# Register Definitions: IP-XACT component
VLNV meklort:<PROJECT>:Register Definitions:1.0

## Address spaces and blocks
APE.APE: base 0xC0010000, range , width , register
APE_PERI.APE_PERI: base 0xC0018000, range , width 

## Registers
Registers are 32-bit, read-write, no defined reset value unless marked. A register's access mark holds for its fields unless they carry their own. Offsets are from the block's base; lines under a group give offsets from that group; [hi:lo] are bit positions; {n}, {i} and the like mark numbered series; 'fields as' and 'values as' point back to an identical list; <NAME> marks a mode.

## APE.APE — Device APE Registers
Base 0xC0010000
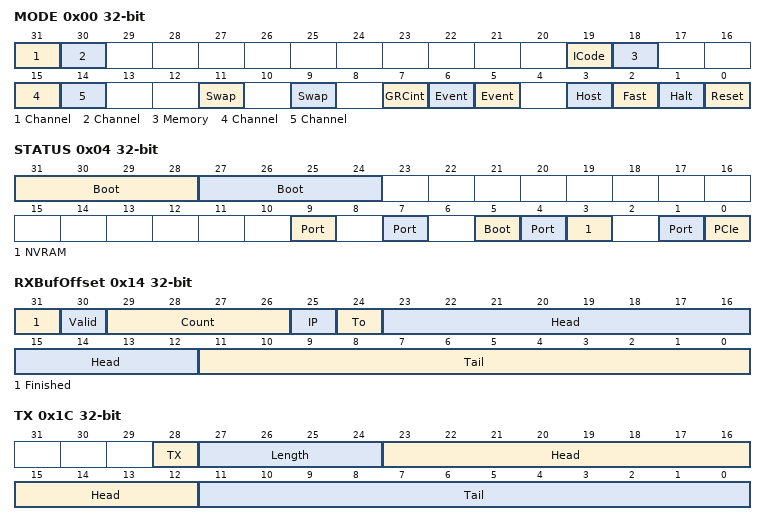
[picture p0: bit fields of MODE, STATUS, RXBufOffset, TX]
0x00 MODE — More of these bits can be found in diagnostic utilities, but they don't seem too interesting.
  [31] Channel 3 Enable
  [30] Channel 1 Enable
  [19] ICode PIP Rd Disable
  [18] Memory ECC
  [15] Channel 2 Enable
  [14] Channel 0 Enable
  [11] Swap ARB dword
  [9] Swap ATB dword
  [7] GRCint
  [6] Event 2
  [5] Event 1 — Used to signal the APE that an event from the host is ready for processing in SHM.
  [3] Host Diag
  [2] Fast Boot — Can be used to boot from RAM instead of NVM. Takes a full APE image with section headers, etc. so you still need to form a proper image.
  [1] Halt — APE is halted if set. Setting then unsetting this bit resets the APE to its reset vector, etc.
  [0] Reset — Used to reset the APE block.
0x04 STATUS
  [31:28] Boot Status A
    0=None; 1=NMI Exception; 2=Fault Exception; 3=Memory Check; 4=Unknown 4; 5=Romloader Disabled; 6=Magic Number; 7=APE Init Code; 8=Header Checksum; 9=APE Header; 10=Image Checksum; 11=NVRAM Checksum; 12=Invalid Type; 13=ROM Loader Checksum; 14=Invalid Unzip Len; 15=Unknown F
  [27:24] Boot Status B
    0=Prog 0; 1=Prog 1; 2=BPC Enter; 3=Decode; 4=Read NVRAM Header; 5=Read Code; 6=Jump; 7=Prog 7; 8=BPC Success
  [9] Port 1 D State — Indicates port is in D3 if set, otherwise the port is in D0-D2.
  [7] Port 1 GRC Reset
  [5] Boot Mode
    0=NVRAM; 1=Fast
  [4] Port 0 D State — Indicates port is in D3 if set, otherwise the port is in D0-D2.
  [3] NVRAM Control Reset
  [1] Port 0 GRC Reset
  [0] PCIe Reset
0x08 GPIO_MESSAGE access not given — Related to APE fastboot. In that case the value of it is an APE memory address in the code region. If Fast Boot is set, and the low two bits of this are not 0b10, ROM hangs (you have to OR 0x2 into the address). Otherwise, they are masked off and the resulting value is used as the reset vector. The resulting value is also stored in this register (i.e., the low two bits are cleared).
0x0C EVENT
  [0] 1 — Event 1
0x14 RXBufOffset Func0 — This is examined on the APE Packet RX interrupt, and indicates the offset of an incoming (from-network) frame within the APE memory space, which provides access to the from-network RX buffer. The fields are block numbers (block size 128 bytes).
  [31] Finished, [30] Valid, [29:26] Count, [25] IP Frag, [24] To Host, [23:12] Head, [11:0] Tail
0x18 RXBufOffset Func1 size not given access not given — This is examined on the APE Packet RX interrupt, and indicates the offset of an incoming (from-network) frame within the APE memory space, which provides access to the from-network RX buffer.
0x1C TX To Net Doorbell Func0 — Written on APE TX to network after filling 0xA002 buffer with packet.
  [28] TX Queue Full, [27:24] Length, [23:12] Head, [11:0] Tail
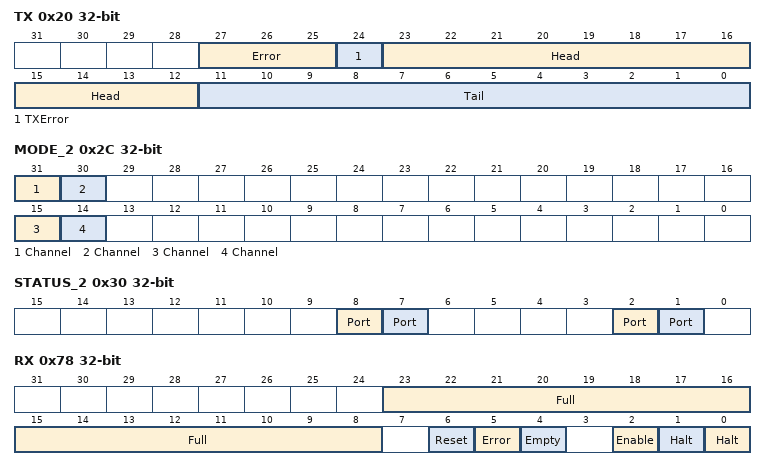
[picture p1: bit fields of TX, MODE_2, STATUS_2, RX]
0x20 TX State0 — APE TX Status Port0
  [27:25] Error Code
    1=Frame Length Mismatch; 2=MBuf Count Mismatch
  [24] TXError
  [23:12] Head
  [11:0] Tail
0x24 TX State1 size not given access not given — APE TX State Port1
0x2C MODE_2 — Expansion for MODE
  [31] Channel 3 Enable, [30] Channel 1 Enable, [15] Channel 2 Enable, [14] Channel 0 Enable
0x30 STATUS_2
  [8] Port 3 D State
  [7] Port 3 GRC Reset — Indicates port is in D3 if set, otherwise the port is in D0-D2.
  [2] Port 2 D State — Indicates port is in D3 if set, otherwise the port is in D0-D2.
  [1] Port 2 GRC Reset
0x4C LOCK_GRANT__OBSOLETE_ access not given — See
0x78 RX Pool Mode Status 0
  [23:8] Full Count, [6] Reset, [5] Error, [4] Empty, [2] Enable, [1] Halt Done, [0] Halt
0x7C RX Pool Mode Status 1 size not given access not given
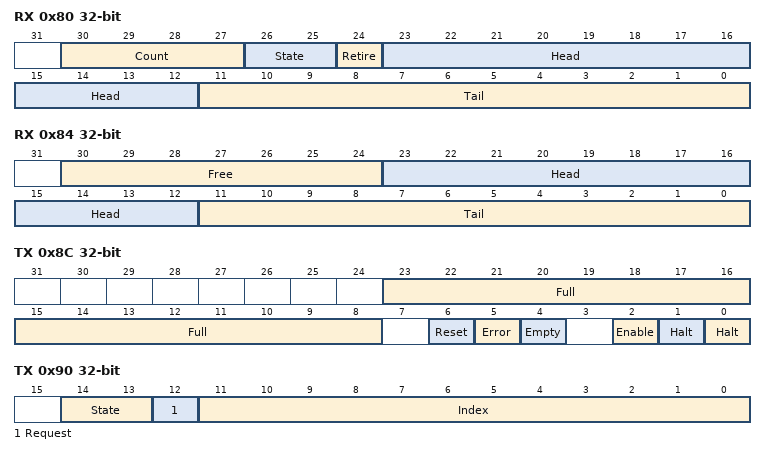
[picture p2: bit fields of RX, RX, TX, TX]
0x80 RX Pool Retire 0 — Used to indicate when the APE is done with a region of the 0xA000_0000 RX pool buffer so that it can be used to receive another frame.
  [30:27] Count
  [26:25] State
    0=Processing; 1=Retired OK; 2=Error: Full; 3=Error: In Halt
  [24] Retire
  [23:12] Head
  [11:0] Tail
0x84 RX Pool Free Pointer 0
  [30:24] Free Count
    127=Max
  [23:12] Head
  [11:0] Tail
0x88 RX Pool Retire 1 size not given access not given — Used to indicate when the APE is done with a region of the 0xA000_0000 RX pool buffer so that it can be used to receive another frame.
0x8C TX To Net Pool Mode Status 0
  [23:8] Full Count
  [6] Reset
  [5] Error
  [4] Empty
  [2] Enable — Must set Enable before the APE TX To Net Buffer Allocator will work.
  [1] Halt Done
  [0] Halt
0x90 TX To Net Buffer Allocator 0
  [14:13] State
    0=Processing; 1=Allocation OK; 2=Error: Empty; 3=Error: In Halt
  [12] Request Allocation
  [11:0] Index
    128=Block Size
0x94 TX To Net Buffer Return 0 access not given
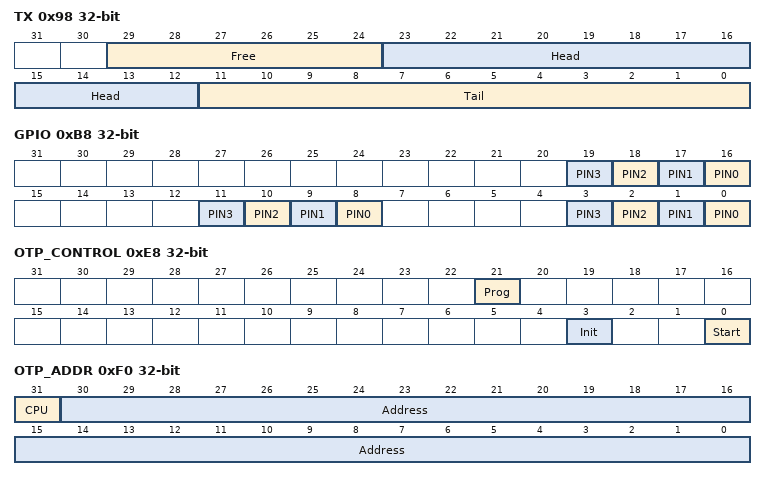
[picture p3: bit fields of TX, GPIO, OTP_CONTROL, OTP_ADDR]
0x98 TX To Net Buffer Ring 0
  [29:24] Free
    63=Max
  [23:12] Head
  [11:0] Tail
0x9C RX Pool Free Pointer 1 size not given access not given
0xA8 Tick 1MHz access not given — Unknown, monotonically increasing value. Increases at a rate of 1MHz.
0xAC Tick 1KHz access not given — Unknown, monotonically increasing value. Increases at a rate of 1KHz.
0xB0 Tick 10Hz access not given — Unknown, monotonically increasing value. Increases at a rate of 10Hz.
0xB8 GPIO
  [n+16] PIN{n} Mode Output (n=0..3), [n+8] PIN{n} Unknown Out (n=0..3), [n] PIN{n} Unknown (n=0..3)
0xBC GINT access not given — TODO: See diag for field info.
0xE8 OTP_CONTROL
  [21] Prog Enable, [3] Init, [0] Start
0xEC OTP_STATUS
  [0] Command Done
0xF0 OTP_ADDR
  [31] CPU Enable, [30:0] Address
0xF8 OTP_READ_DATA access not given
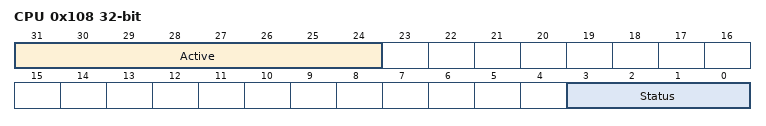
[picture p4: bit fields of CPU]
0x108 CPU Status — Seems CPU control related.
  [31:24] Active Interrupt
  [3:0] Status
    0=Running; 1=Halted; 2=Locked Out; 3=Sleeping; 4=Deep Sleep; 8=Interrupt Pending; 9=Interrupt Entry; 10=Interrupt Exit; 11=Interrupt Return
0x110 TX To Net Pool Mode Status 1 size not given access not given
0x114 TX To Net Buffer Allocator 1 size not given access not given
0x118 TX To Net Buffer Return 1 size not given access not given
0x11C TX To Net Buffer Ring 1 size not given access not given
0x120 TX To Net Doorbell Func1 size not given access not given — Written on APE TX to network after filling 0xA002 buffer with packet.
0x200 RXBufOffset Func2 size not given access not given — This is examined on the APE Packet RX interrupt, and indicates the offset of an incoming (from-network) frame within the APE memory space, which provides access to the from-network RX buffer.
0x204 TX To Net Doorbell Func2 size not given access not given — Written on APE TX to network after filling 0xA002 buffer with packet.
0x208 TX State2 size not given access not given — APE TX State Port2
0x214 RX Pool Mode Status 2 size not given access not given
0x218 RX Pool Retire 2 size not given access not given — Used to indicate when the APE is done with a region of the 0xA000_0000 RX pool buffer so that it can be used to receive another frame.
0x21C RX Pool Free Pointer 2 size not given access not given
0x220 TX To Net Pool Mode Status 2 size not given access not given
0x224 TX To Net Buffer Allocator 2 size not given access not given
0x228 TX To Net Buffer Return 2 size not given access not given
0x22C TX To Net Buffer Ring 2 size not given access not given
0x300 RXBufOffset Func3 size not given access not given — This is examined on the APE Packet RX interrupt, and indicates the offset of an incoming (from-network) frame within the APE memory space, which provides access to the from-network RX buffer.
0x304 TX To Net Doorbell Func3 size not given access not given — Written on APE TX to network after filling 0xA002 buffer with packet.
0x308 TX State3 size not given access not given — APE TX State Port3
0x314 RX Pool Mode Status 3 size not given access not given
0x318 RX Pool Retire 3 size not given access not given — Used to indicate when the APE is done with a region of the 0xA000_0000 RX pool buffer so that it can be used to receive another frame.
0x31C RX Pool Free Pointer 3 size not given access not given
0x320 TX To Net Pool Mode Status 3 size not given access not given
0x324 TX To Net Buffer Allocator 3 size not given access not given
0x328 TX To Net Buffer Return 3 size not given access not given
0x32C TX To Net Buffer Ring 3 size not given access not given

## APE_PERI.APE_PERI — Device APE Peripheral Registers
Base 0xC0018000
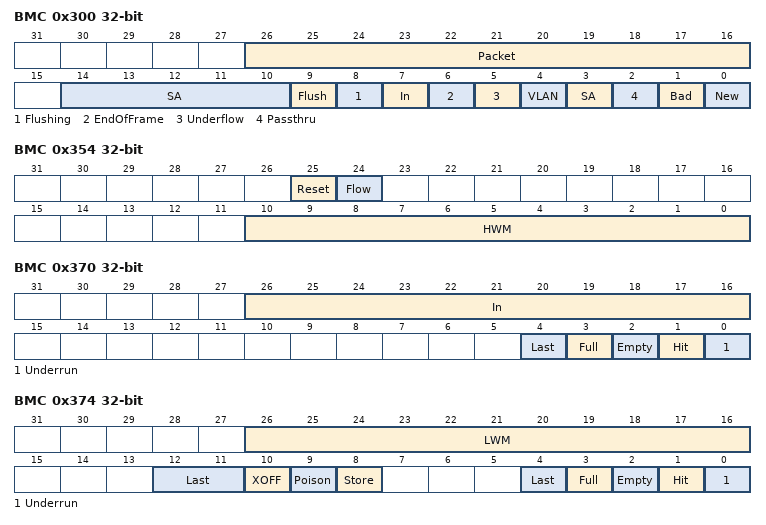
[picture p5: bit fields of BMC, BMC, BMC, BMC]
0x300 BMC to NC RX Status
  [26:16] Packet Length, [14:10] SA hit, [9] Flush Done, [8] Flushing, [7] In Progress, [6] EndOfFrame, [5] Underflow, [4] VLAN, [3] SA Hit Valid, [2] Passthru, [1] Bad, [0] New
0x304 BMC to NC Source MAC High — Upper four bytes of the MAC
  [31:0] High
0x308 BMC to NC Source MAC Low — Lower two bytes of the MAC
  [31:16] Low
{0x30C+8i} BMC to NC Source MAC Match {i} High (i=0..7) — Upper four bytes of the MAC
  [31:0] High
{0x310+8i} BMC to NC Source MAC Match {i} Low (i=0..7) — Lower two bytes of the MAC
  [31:16] Low
0x34C BMC to NC RX VLAN
  [31:16] VLAN
0x350 BMC to NC Read Buffer access not given
0x354 BMC to NC RX Control
  [25] Reset Bad — Or'd after receiving Status.Bad frame
  [24] Flow Control
  [10:0] HWM
0x358 BMC to NC RX Status 1 access not given
0x35C BMC to NC RX Status 2 access not given
0x370 BMC to NC TX Status
  [26:16] In Fifo, [4] Last Full Count, [3] Full, [2] Empty, [1] Hit LWM, [0] Underrun
0x374 BMC to NC TX Control
  [26:16] LWM, [12:11] Last Byte Count, [10] XOFF, [9] Poison, [8] Store Forward, [4] Last Full Count, [3] Full, [2] Empty, [1] Hit LWM, [0] Underrun
0x378 BMC to NC TX Buffer access not given
0x37C BMC to NC TX Buffer Last access not given
0x380 BMC to NC TX Status 1 access not given
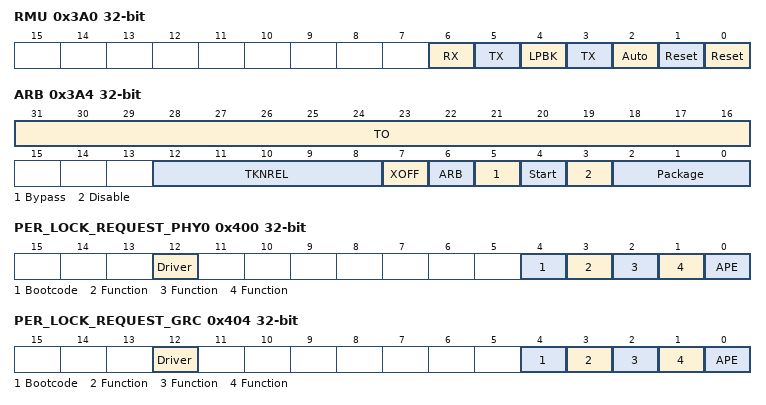
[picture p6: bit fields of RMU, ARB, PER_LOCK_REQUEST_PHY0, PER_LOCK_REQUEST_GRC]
0x3A0 RMU Control
  [6] RX, [5] TX, [4] LPBK, [3] TX Drv, [2] Auto Drv, [1] Reset RX, [0] Reset TX
0x3A4 ARB Control
  [31:16] TO
  [12:8] TKNREL
  [7] XOFF Disable
  [6] ARB Bypass
  [5] Bypass
  [4] Start
  [3] Disable
  [2:0] Package ID — NC-SI Package ID
0x400 PER_LOCK_REQUEST_PHY0 — This register, and the following Per Lock Request registers work the same. The tg3 driver uses 0x0000_1000 (APELOCK_PER_REQ_DRIVER) for PHY ports (or always for function 0).
  [12] Driver, [4] Bootcode, [3] Function 3, [2] Function 2, [1] Function 1, [0] APE
0x404 PER_LOCK_REQUEST_GRC
  fields as PER_LOCK_REQUEST_PHY0
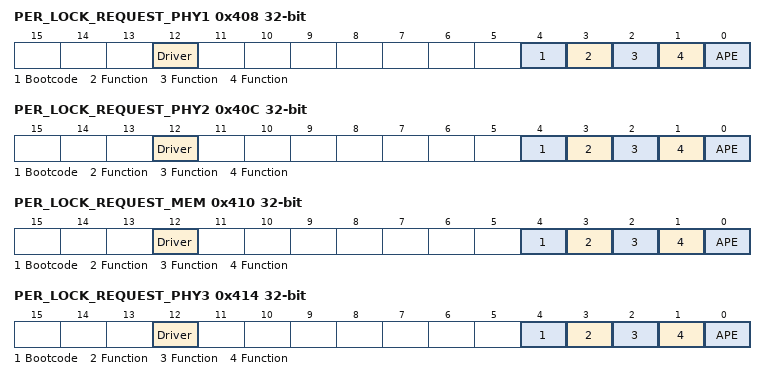
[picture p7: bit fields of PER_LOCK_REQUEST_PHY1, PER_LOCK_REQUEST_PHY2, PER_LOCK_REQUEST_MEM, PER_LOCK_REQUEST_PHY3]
0x408 PER_LOCK_REQUEST_PHY1
  fields as PER_LOCK_REQUEST_PHY0
0x40C PER_LOCK_REQUEST_PHY2
  fields as PER_LOCK_REQUEST_PHY0
0x410 PER_LOCK_REQUEST_MEM
  fields as PER_LOCK_REQUEST_PHY0
0x414 PER_LOCK_REQUEST_PHY3
  fields as PER_LOCK_REQUEST_PHY0
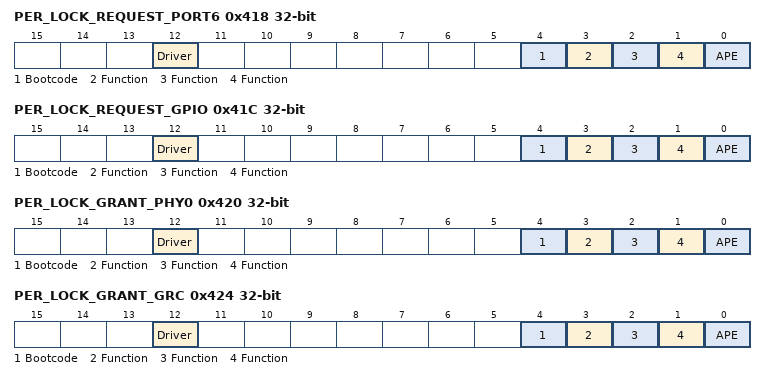
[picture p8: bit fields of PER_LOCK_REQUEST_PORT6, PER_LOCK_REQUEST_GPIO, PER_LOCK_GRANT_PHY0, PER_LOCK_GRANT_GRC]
0x418 PER_LOCK_REQUEST_PORT6
  fields as PER_LOCK_REQUEST_PHY0
0x41C PER_LOCK_REQUEST_GPIO
  fields as PER_LOCK_REQUEST_PHY0
0x420 PER_LOCK_GRANT_PHY0
  fields as PER_LOCK_REQUEST_PHY0
0x424 PER_LOCK_GRANT_GRC
  fields as PER_LOCK_REQUEST_PHY0
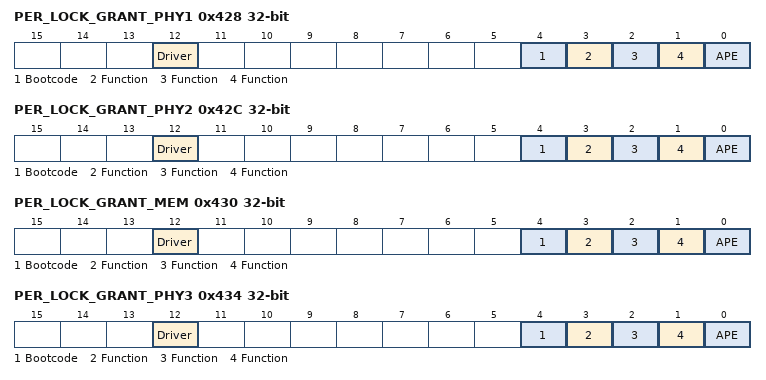
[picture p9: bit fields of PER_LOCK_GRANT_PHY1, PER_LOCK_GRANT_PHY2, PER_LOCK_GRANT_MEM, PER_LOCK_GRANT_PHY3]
0x428 PER_LOCK_GRANT_PHY1
  fields as PER_LOCK_REQUEST_PHY0
0x42C PER_LOCK_GRANT_PHY2
  fields as PER_LOCK_REQUEST_PHY0
0x430 PER_LOCK_GRANT_MEM
  fields as PER_LOCK_REQUEST_PHY0
0x434 PER_LOCK_GRANT_PHY3
  fields as PER_LOCK_REQUEST_PHY0
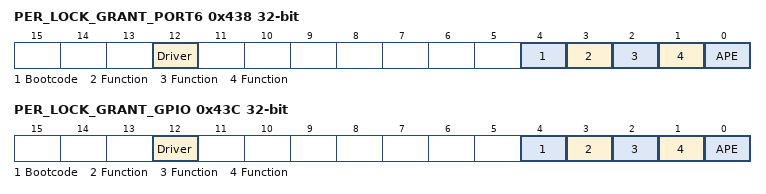
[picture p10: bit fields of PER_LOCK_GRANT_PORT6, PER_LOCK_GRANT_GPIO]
0x438 PER_LOCK_GRANT_PORT6
  fields as PER_LOCK_REQUEST_PHY0
0x43C PER_LOCK_GRANT_GPIO
  fields as PER_LOCK_REQUEST_PHY0
